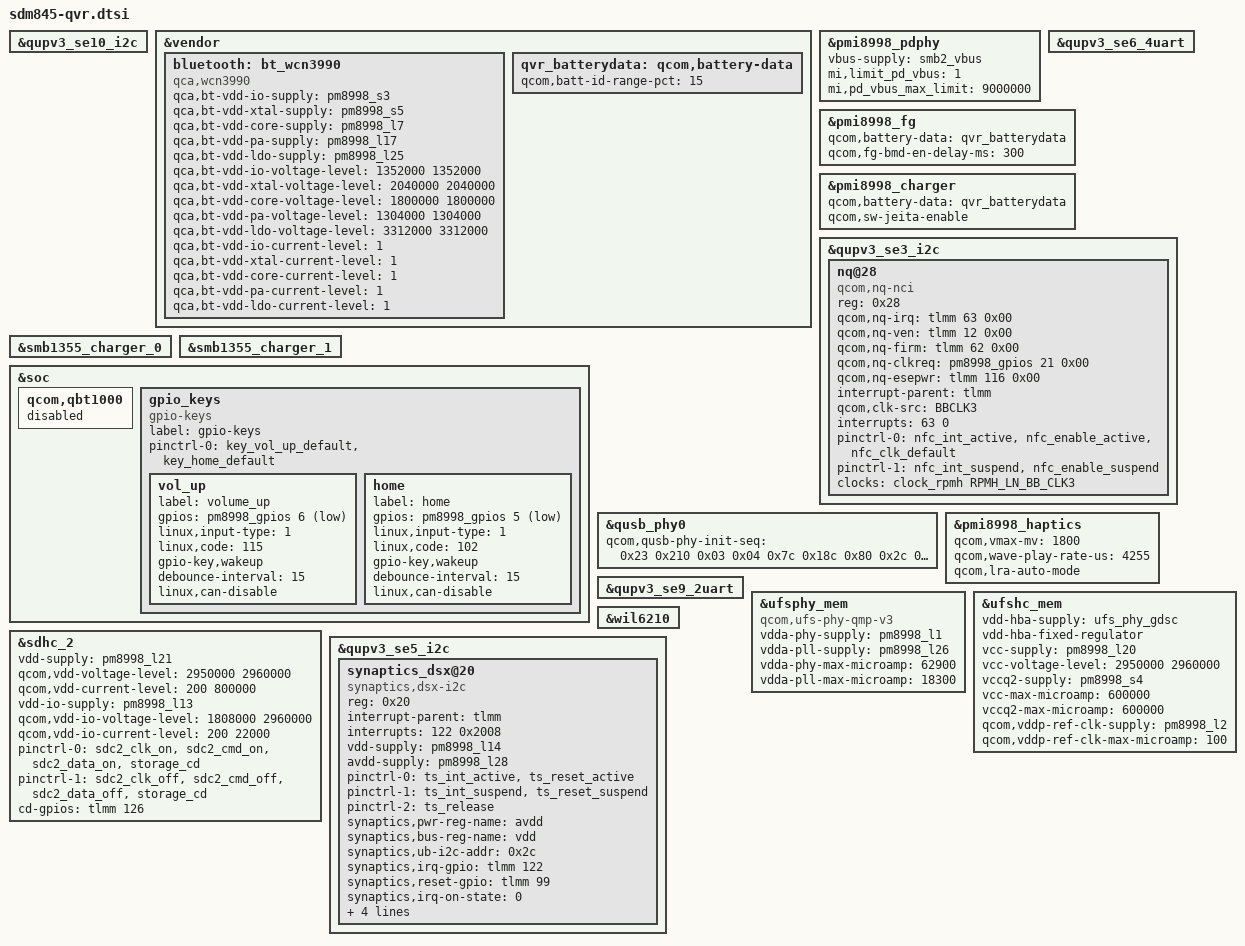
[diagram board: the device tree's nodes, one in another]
/* Copyright (c) 2017-2018, The Linux Foundation. All rights reserved.
 * Copyright (C) 2019 XiaoMi, Inc.
 *
 * This program is free software; you can redistribute it and/or modify
 * it under the terms of the GNU General Public License version 2 and
 * only version 2 as published by the Free Software Foundation.
 *
 * This program is distributed in the hope that it will be useful,
 * but WITHOUT ANY WARRANTY; without even the implied warranty of
 * MERCHANTABILITY or FITNESS FOR A PARTICULAR PURPOSE.  See the
 * GNU General Public License for more details.
 */

#include <dt-bindings/clock/qcom,gcc-sdm845.h>
#include <dt-bindings/clock/qcom,camcc-sdm845.h>
#include <dt-bindings/clock/qcom,dispcc-sdm845.h>
#include <dt-bindings/clock/qcom,rpmh.h>
#include <dt-bindings/interrupt-controller/arm-gic.h>

#include "sdm845-pmic-overlay.dtsi"
#include "sdm845-pinctrl-overlay.dtsi"

&qupv3_se10_i2c {
#include "smb1355.dtsi"
};

&vendor {
	bluetooth: bt_wcn3990 {
		compatible = "qca,wcn3990";
		qca,bt-vdd-io-supply = <&pm8998_s3>;
		qca,bt-vdd-xtal-supply = <&pm8998_s5>;
		qca,bt-vdd-core-supply = <&pm8998_l7>;
		qca,bt-vdd-pa-supply = <&pm8998_l17>;
		qca,bt-vdd-ldo-supply = <&pm8998_l25>;

		qca,bt-vdd-io-voltage-level = <1352000 1352000>;
		qca,bt-vdd-xtal-voltage-level = <2040000 2040000>;
		qca,bt-vdd-core-voltage-level = <1800000 1800000>;
		qca,bt-vdd-pa-voltage-level = <1304000 1304000>;
		qca,bt-vdd-ldo-voltage-level = <3312000 3312000>;

		qca,bt-vdd-io-current-level = <1>; /* LPM/PFM */
		qca,bt-vdd-xtal-current-level = <1>; /* LPM/PFM */
		qca,bt-vdd-core-current-level = <1>; /* LPM/PFM */
		qca,bt-vdd-pa-current-level = <1>; /* LPM/PFM */
		qca,bt-vdd-ldo-current-level = <1>; /* LPM/PFM */
	};

	qvr_batterydata: qcom,battery-data {
		qcom,batt-id-range-pct = <15>;
		#include "fg-gen3-batterydata-mlp446579-3800mah.dtsi"
	};
};

&pmi8998_pdphy {
	vbus-supply = <&smb2_vbus>;
	/*mi,limit_pd_vbus 1:enable 0:disable*/
	mi,limit_pd_vbus = <1>;
	mi,pd_vbus_max_limit = <9000000>;
};

&qupv3_se6_4uart {
	status = "ok";
};

&pmi8998_fg {
	qcom,battery-data = <&qvr_batterydata>;
	qcom,fg-bmd-en-delay-ms = <300>;
};

&pmi8998_charger {
	qcom,battery-data = <&qvr_batterydata>;
	qcom,sw-jeita-enable;
};

&qupv3_se3_i2c {
	status = "ok";
	nq@28 {
		compatible = "qcom,nq-nci";
		reg = <0x28>;
		qcom,nq-irq = <&tlmm 63 0x00>;
		qcom,nq-ven = <&tlmm 12 0x00>;
		qcom,nq-firm = <&tlmm 62 0x00>;
		qcom,nq-clkreq = <&pm8998_gpios 21 0x00>;
		qcom,nq-esepwr = <&tlmm 116 0x00>;
		interrupt-parent = <&tlmm>;
		qcom,clk-src = "BBCLK3";
		interrupts = <63 0>;
		interrupt-names = "nfc_irq";
		pinctrl-names = "nfc_active", "nfc_suspend";
		pinctrl-0 = <&nfc_int_active
			     &nfc_enable_active
			     &nfc_clk_default>;
		pinctrl-1 = <&nfc_int_suspend &nfc_enable_suspend>;
		clocks = <&clock_rpmh RPMH_LN_BB_CLK3>;
		clock-names = "ref_clk";
	};
};

&qupv3_se10_i2c {
	status = "ok";
};

&smb1355_charger_0 {
	status = "ok";
};

&smb1355_charger_1 {
	status = "ok";
};

&soc {
	qcom,qbt1000 {
		status = "disabled";
	};

	gpio_keys {
		compatible = "gpio-keys";
		label = "gpio-keys";
		pinctrl-names = "default";
		pinctrl-0 = <&key_vol_up_default
			     &key_home_default>;

		vol_up {
			label = "volume_up";
			gpios = <&pm8998_gpios 6 GPIO_ACTIVE_LOW>;
			linux,input-type = <1>;
			linux,code = <115>;
			gpio-key,wakeup;
			debounce-interval = <15>;
			linux,can-disable;
		};

		home {
			label = "home";
			gpios = <&pm8998_gpios 5 GPIO_ACTIVE_LOW>;
			linux,input-type = <1>;
			linux,code = <102>;
			gpio-key,wakeup;
			debounce-interval = <15>;
			linux,can-disable;
		};
	};
};

&qusb_phy0 {
		qcom,qusb-phy-init-seq =
			/* <value reg_offset> */
			   <0x23 0x210 /* PWR_CTRL1 */
			    0x03 0x04  /* PLL_ANALOG_CONTROLS_TWO */
			    0x7c 0x18c /* PLL_CLOCK_INVERTERS */
			    0x80 0x2c  /* PLL_CMODE */
			    0x0a 0x184 /* PLL_LOCK_DELAY */
			    0x19 0xb4  /* PLL_DIGITAL_TIMERS_TWO */
			    0x40 0x194 /* PLL_BIAS_CONTROL_1 */
			    0x20 0x198 /* PLL_BIAS_CONTROL_2 */
			    0x21 0x214 /* PWR_CTRL2 */
			    0x00 0x220 /* IMP_CTRL1 */
			    0x58 0x224 /* IMP_CTRL2 */
			    0x27 0x240 /* TUNE1 */
			    0x29 0x244 /* TUNE2 */
			    0xca 0x248 /* TUNE3 */
			    0x04 0x24c /* TUNE4 */
			    0x03 0x250 /* TUNE5 */
			    0x00 0x23c /* CHG_CTRL2 */
			    0x22 0x210>; /* PWR_CTRL1 */
};

&pmi8998_haptics {
	qcom,vmax-mv = <1800>;
	qcom,wave-play-rate-us = <4255>;
	qcom,lra-auto-mode;
	status = "okay";
};

&qupv3_se9_2uart {
	status = "ok";
};

&ufsphy_mem {
	compatible = "qcom,ufs-phy-qmp-v3";

	vdda-phy-supply = <&pm8998_l1>; /* 0.88v */
	vdda-pll-supply = <&pm8998_l26>; /* 1.2v */
	vdda-phy-max-microamp = <62900>;
	vdda-pll-max-microamp = <18300>;

	status = "ok";
};

&ufshc_mem {
	vdd-hba-supply = <&ufs_phy_gdsc>;
	vdd-hba-fixed-regulator;
	vcc-supply = <&pm8998_l20>;
	vcc-voltage-level = <2950000 2960000>;
	vccq2-supply = <&pm8998_s4>;
	vcc-max-microamp = <600000>;
	vccq2-max-microamp = <600000>;

	qcom,vddp-ref-clk-supply = <&pm8998_l2>;
	qcom,vddp-ref-clk-max-microamp = <100>;

	status = "ok";
};

&sdhc_2 {
	vdd-supply = <&pm8998_l21>;
	qcom,vdd-voltage-level = <2950000 2960000>;
	qcom,vdd-current-level = <200 800000>;

	vdd-io-supply = <&pm8998_l13>;
	qcom,vdd-io-voltage-level = <1808000 2960000>;
	qcom,vdd-io-current-level = <200 22000>;

	pinctrl-names = "active", "sleep";
	pinctrl-0 = <&sdc2_clk_on  &sdc2_cmd_on &sdc2_data_on &storage_cd>;
	pinctrl-1 = <&sdc2_clk_off &sdc2_cmd_off &sdc2_data_off &storage_cd>;

	cd-gpios = <&tlmm 126 GPIO_ACTIVE_HIGH>;

	status = "ok";
};

&wil6210 {
	status = "ok";
};

&qupv3_se5_i2c {
	status = "ok";
	synaptics_dsx@20 {
		compatible = "synaptics,dsx-i2c";
		reg = <0x20>;
		interrupt-parent = <&tlmm>;
		interrupts = <122 0x2008>;
		vdd-supply = <&pm8998_l14>;
		avdd-supply = <&pm8998_l28>;
		pinctrl-names = "pmx_ts_active", "pmx_ts_suspend",
				"pmx_ts_release";
		pinctrl-0 = <&ts_int_active &ts_reset_active>;
		pinctrl-1 = <&ts_int_suspend &ts_reset_suspend>;
		pinctrl-2 = <&ts_release>;
		synaptics,pwr-reg-name = "avdd";
		synaptics,bus-reg-name = "vdd";
		synaptics,ub-i2c-addr = <0x2c>;
		synaptics,irq-gpio = <&tlmm 122 0x2008>;
		synaptics,reset-gpio = <&tlmm 99 0x0>;
		synaptics,irq-on-state = <0>;
		synaptics,power-delay-ms = <200>;
		synaptics,reset-delay-ms = <200>;
		synaptics,reset-on-state = <0>;
		synaptics,reset-active-ms = <20>;
	};
};
